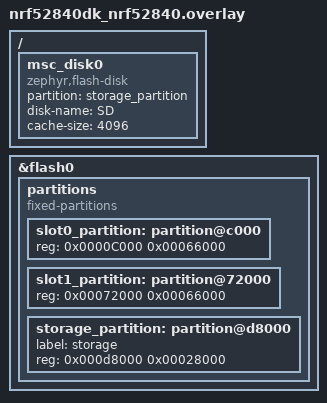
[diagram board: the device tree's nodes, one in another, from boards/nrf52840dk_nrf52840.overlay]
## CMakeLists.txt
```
cmake_minimum_required(VERSION 3.20.0)
find_package(Zephyr REQUIRED HINTS $ENV{ZEPHYR_BASE})

project(app LANGUAGES C)

target_sources(app PRIVATE src/main.cpp)
```

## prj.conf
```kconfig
# This file contains selected Kconfig options for the application.

# Enable the library.
CONFIG_FS_MODULE=y

# Disable Segger J-Link RTT
CONFIG_USE_SEGGER_RTT=n

# Enable logging.
CONFIG_LOG=y
# Disables colouring of errors (red) and warnings (yellow).
CONFIG_LOG_BACKEND_SHOW_COLOR=n
# Log immediately instead of deterred.
CONFIG_LOG_MODE_IMMEDIATE=y

# C++ Language Support
CONFIG_CPP=y
CONFIG_STD_CPP20=y
CONFIG_REQUIRES_FULL_LIBCPP=y
# The library throws exceptions instead of rturning error codes.
CONFIG_CPP_EXCEPTIONS=y

# File System
CONFIG_DISK_ACCESS=y
CONFIG_FILE_SYSTEM=y
CONFIG_FAT_FILESYSTEM_ELM=y
# Disable internal file system logging, we want to do all logging ourselves.
CONFIG_FS_LOG_LEVEL_OFF=y
CONFIG_FLASHDISK_LOG_LEVEL_OFF=y
# Allow file system formatting.
CONFIG_FILE_SYSTEM_MKFS=y
```

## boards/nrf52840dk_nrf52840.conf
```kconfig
CONFIG_DISK_DRIVERS=y
CONFIG_DISK_DRIVER_FLASH=y
```

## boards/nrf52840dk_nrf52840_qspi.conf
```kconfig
#
# Copyright (c) 2023 Nordic Semiconductor ASA
#
# SPDX-License-Identifier: Apache-2.0
#

CONFIG_NORDIC_QSPI_NOR=y
# The mx25 erase page size
CONFIG_NORDIC_QSPI_NOR_FLASH_LAYOUT_PAGE_SIZE=4096
CONFIG_DISK_DRIVERS=y
CONFIG_DISK_DRIVER_FLASH=y
```

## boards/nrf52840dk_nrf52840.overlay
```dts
/* Because FAT FS needs at least 64 kiB partition and default
 * storage_partition is 32kiB for that board, we need to reorganize
 * partitions to get at least 64 KiB.
 * This overlay removes image slot partitions and strips each of 64 kiB,
 * and removes the storage partition to add the additional 2 * 64 kiB to
 * it.
 */
 /delete-node/ &slot0_partition;
 /delete-node/ &slot1_partition;
 /delete-node/ &storage_partition;
 
 &flash0 {
	partitions {
		compatible = "fixed-partitions";
		#address-cells = <1>;
		#size-cells = <1>;
 
		slot0_partition: partition@c000 {
			reg = <0x0000C000 0x00066000>;
		};
		slot1_partition: partition@72000 {
			reg = <0x00072000 0x00066000>;
		};
 
		storage_partition: partition@d8000 {
			label = "storage";
			reg = <0x000d8000 0x00028000>;
		};
	 };
 };
 
 / {
	 msc_disk0 {
		status = "okay";
		compatible = "zephyr,flash-disk";
		partition = <&storage_partition>;
		disk-name = "SD";
		// cache-size is page erase size
		cache-size = <4096>;
	 };
 };
```

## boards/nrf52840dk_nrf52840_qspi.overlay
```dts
/* Note that default partition layout, provided by board DTS, is not
 * altered here as external_partition used by the disk is defined
 * over QSPI device and does not collide with any other partition
 * definition.
 */

 &mx25r64 {
	partitions {
		compatible = "fixed-partitions";
		#address-cells = <1>;
		#size-cells = <1>;

		// external storage partition 8388608 bytes
		external_partition: partition@0 {
			reg = <0x00000000 0x00800000>;
		};
	};
};

/ {
	msc_disk0 {
		status="okay";
		compatible = "zephyr,flash-disk";
		partition = <&external_partition>;
		disk-name = "SD";
		// cache-size == page erase size
		cache-size = <4096>;
	};
};
```

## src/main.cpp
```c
#include <zephyr/drivers/flash.h>
#include <zephyr/kernel.h>
#include <zephyr/logging/log.h>

LOG_MODULE_REGISTER(main);

#if CONFIG_FS_MODULE

#include <fs-module/FileSystem.hpp>
#include <fs-module/FileSystemFormatException.hpp>
#include <fs-module/FileSystemMountException.hpp>
#include <fs-module/FileSystemUnmountException.hpp>
#include <fs-module/fat/FatFileSystem.hpp>

#define FORMAT_FS 0

const std::string FS_MNTP = "/SD:";

int main() {
    // Instance of file system.
    std::unique_ptr<FileSystem> file_system = std::make_unique<FatFileSystem>();

#if FORMAT_FS

    // Format file system volume.
    try {
        file_system->format();
        LOG_INF("%s", "Formatted file system volume.");
    } catch (const FileSystemFormatException &e) {
        LOG_ERR("Failed to format file system volume: %s", e.what());
    }

#endif

    // Mount file system.
    try {
        file_system->mount(FS_MNTP);
        LOG_INF("%s", "Mounted file system.");
    } catch (const FileSystemMountException &e) {
        LOG_ERR("Failed to mount file system: %s", e.what());
    }

    // Unmount file system.
    try {
        file_system->unmount();
        LOG_INF("%s", "Unmounted file system.");
    } catch (const FileSystemUnmountException &e) {
        LOG_ERR("Failed to unmount file system: %s", e.what());
    }

    return 0;
}

#else

int main() {
    LOG_WRN("File system module is not enabled.");
    return 0;
}

#endif
```
